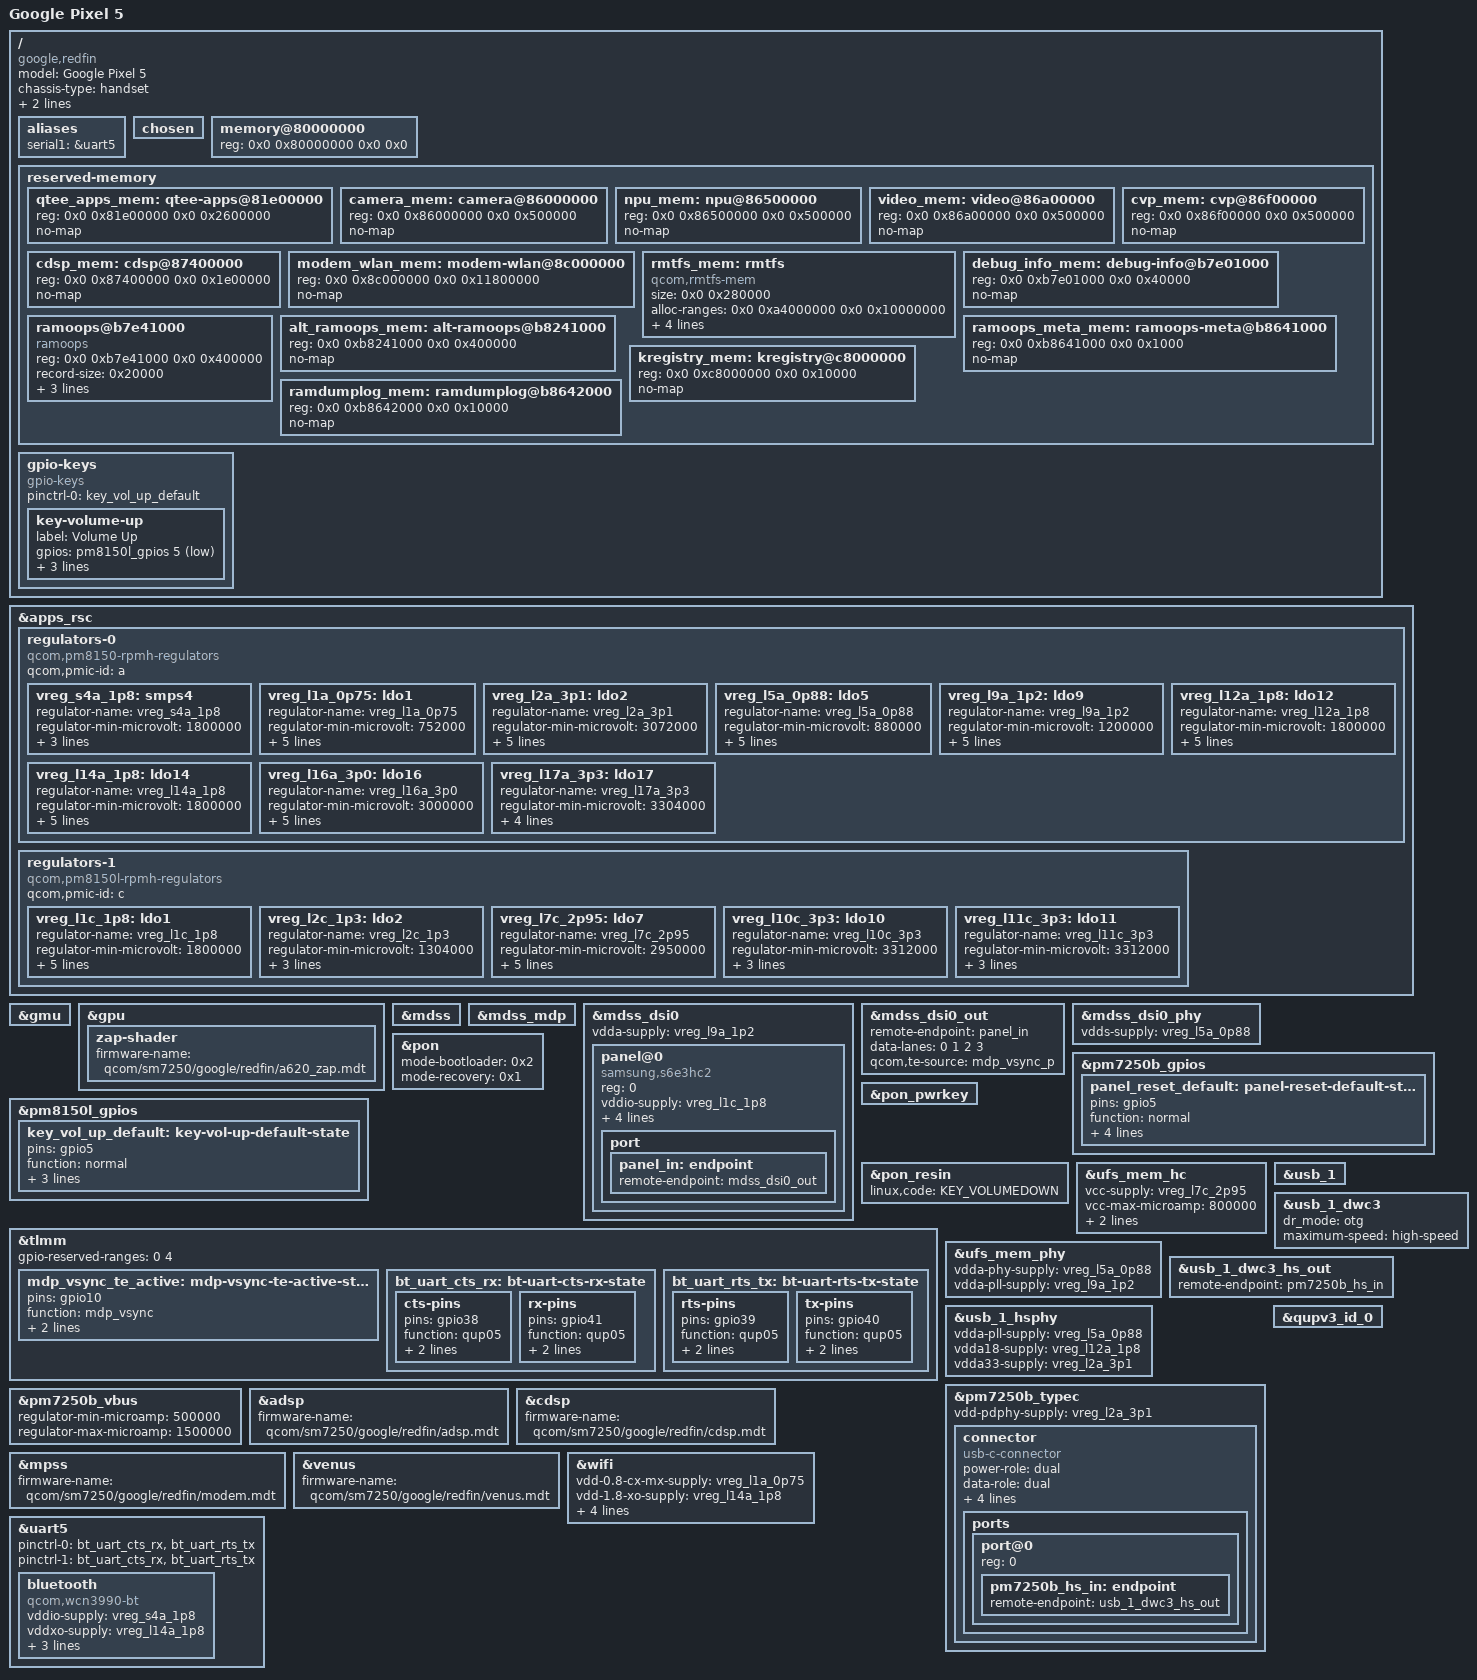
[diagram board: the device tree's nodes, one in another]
// SPDX-License-Identifier: BSD-3-Clause
/*
 * Device Tree for Google Pixel 5 (redfin) - Qualcomm Snapdragon 765G (SM7250)
 * Based on sm7250-oneplus-avicii.dts and Google Redfin stock DT (RQ3A.211001.001).
 */

/dts-v1/;

#include <dt-bindings/gpio/gpio.h>
#include <dt-bindings/input/input.h>
#include <dt-bindings/leds/common.h>
#include <dt-bindings/input/linux-event-codes.h>
#include <dt-bindings/pinctrl/qcom,pmic-gpio.h>
#include <dt-bindings/regulator/qcom,rpmh-regulator.h>

/* PM7250B is configured to use SID2/3 */
#define PM7250B_SID 2
#define PM7250B_SID1 3

#include "sm7250.dtsi"
#include "pm8150.dtsi"
#include "pm8150l.dtsi"
#include "pm7250b.dtsi"

/*
 * Remove the OnePlus OxygenOS 12 relocated PIL nodes from sm7250.dtsi
 * (0x9b800000..0x9cc00000) because Redfin uses the standard Lito layout
 * (0x86000000..0x87400000) and expands modem_wlan_mem to 0x8c000000..0x9d800000.
 */
/delete-node/ &camera_mem;
/delete-node/ &npu_mem;
/delete-node/ &video_mem;
/delete-node/ &cvp_mem;
/delete-node/ &cdsp_mem;

/ {
	model = "Google Pixel 5";
	compatible = "google,redfin", "qcom,sm7250";
	chassis-type = "handset";

	/* Matches Redfin PVT (MP1.0) in stock dtbo_1.dts */
	qcom,msm-id = <0x190 0x20000 0x1b8 0x20000>;
	qcom,board-id = <0xb1e05 0x0>;

	aliases {
		serial1 = &uart5;
	};

	chosen {
	};

	memory@80000000 {
		device_type = "memory";
		reg = <0x0 0x80000000 0x0 0x0>;
	};

	reserved-memory {
		qtee_apps_mem: qtee-apps@81e00000 {
			reg = <0x0 0x81e00000 0x0 0x2600000>;
			no-map;
		};

		camera_mem: camera@86000000 {
			reg = <0x0 0x86000000 0x0 0x500000>;
			no-map;
		};

		npu_mem: npu@86500000 {
			reg = <0x0 0x86500000 0x0 0x500000>;
			no-map;
		};

		video_mem: video@86a00000 {
			reg = <0x0 0x86a00000 0x0 0x500000>;
			no-map;
		};

		cvp_mem: cvp@86f00000 {
			reg = <0x0 0x86f00000 0x0 0x500000>;
			no-map;
		};

		cdsp_mem: cdsp@87400000 {
			reg = <0x0 0x87400000 0x0 0x1e00000>;
			no-map;
		};

		modem_wlan_mem: modem-wlan@8c000000 {
			reg = <0x0 0x8c000000 0x0 0x11800000>;
			no-map;
		};

		/*
		 * rmtfs shared memory for MPSS (client 1, size 0x280000),
		 * placed in free RAM above dfps_data_mem (0xa2400000).
		 */
		rmtfs_mem: rmtfs {
			compatible = "qcom,rmtfs-mem";
			size = <0x0 0x280000>;
			alloc-ranges = <0x0 0xa4000000 0x0 0x10000000>;
			alignment = <0x0 0x400000>;
			no-map;

			qcom,client-id = <1>;
			qcom,vmid = <15>; /* QCOM_SCM_VMID_MSS_MSA */
		};

		/* Redfin stock debug & ramoops regions (dtbo_1.dts fragment@60 & fragment@74) */
		debug_info_mem: debug-info@b7e01000 {
			reg = <0x0 0xb7e01000 0x0 0x40000>;
			no-map;
		};

		ramoops@b7e41000 {
			compatible = "ramoops";
			reg = <0x0 0xb7e41000 0x0 0x400000>;
			record-size = <0x20000>;
			console-size = <0x100000>;
			pmsg-size = <0x80000>;
			no-map;
		};

		alt_ramoops_mem: alt-ramoops@b8241000 {
			reg = <0x0 0xb8241000 0x0 0x400000>;
			no-map;
		};

		ramoops_meta_mem: ramoops-meta@b8641000 {
			reg = <0x0 0xb8641000 0x0 0x1000>;
			no-map;
		};

		ramdumplog_mem: ramdumplog@b8642000 {
			reg = <0x0 0xb8642000 0x0 0x10000>;
			no-map;
		};

		kregistry_mem: kregistry@c8000000 {
			reg = <0x0 0xc8000000 0x0 0x10000>;
			no-map;
		};
	};

	gpio-keys {
		compatible = "gpio-keys";
		pinctrl-names = "default";
		pinctrl-0 = <&key_vol_up_default>;

		key-volume-up {
			label = "Volume Up";
			gpios = <&pm8150l_gpios 5 GPIO_ACTIVE_LOW>;
			linux,code = <KEY_VOLUMEUP>;
			debounce-interval = <15>;
			wakeup-source;
		};
	};
};

&apps_rsc {
	regulators-0 {
		compatible = "qcom,pm8150-rpmh-regulators";
		qcom,pmic-id = "a";

		/* UFS vccq2 & system 1.8 V rail */
		vreg_s4a_1p8: smps4 {
			regulator-name = "vreg_s4a_1p8";
			regulator-min-microvolt = <1800000>;
			regulator-max-microvolt = <1800000>;
			regulator-boot-on;
			regulator-always-on;
		};

		/* WLAN vdd-0.8-cx-mx */
		vreg_l1a_0p75: ldo1 {
			regulator-name = "vreg_l1a_0p75";
			regulator-min-microvolt = <752000>;
			regulator-max-microvolt = <752000>;
			regulator-initial-mode = <RPMH_REGULATOR_MODE_HPM>;
			regulator-boot-on;
			regulator-always-on;
		};

		/* USB HS PHY 3.1 V & Type-C PD PHY */
		vreg_l2a_3p1: ldo2 {
			regulator-name = "vreg_l2a_3p1";
			regulator-min-microvolt = <3072000>;
			regulator-max-microvolt = <3072000>;
			regulator-initial-mode = <RPMH_REGULATOR_MODE_HPM>;
			regulator-boot-on;
			regulator-always-on;
		};

		/* USB HS PHY PLL, UFS PHY vdda, DSI0 PHY vdds (0.88 V) */
		vreg_l5a_0p88: ldo5 {
			regulator-name = "vreg_l5a_0p88";
			regulator-min-microvolt = <880000>;
			regulator-max-microvolt = <880000>;
			regulator-initial-mode = <RPMH_REGULATOR_MODE_HPM>;
			regulator-boot-on;
			regulator-always-on;
		};

		/* UFS PHY PLL & DSI0 vdda (1.2 V) */
		vreg_l9a_1p2: ldo9 {
			regulator-name = "vreg_l9a_1p2";
			regulator-min-microvolt = <1200000>;
			regulator-max-microvolt = <1200000>;
			regulator-initial-mode = <RPMH_REGULATOR_MODE_HPM>;
			regulator-boot-on;
			regulator-always-on;
		};

		/* USB HS PHY 1.8 V */
		vreg_l12a_1p8: ldo12 {
			regulator-name = "vreg_l12a_1p8";
			regulator-min-microvolt = <1800000>;
			regulator-max-microvolt = <1800000>;
			regulator-initial-mode = <RPMH_REGULATOR_MODE_HPM>;
			regulator-boot-on;
			regulator-always-on;
		};

		/* WLAN/BT vdd-1.8-xo */
		vreg_l14a_1p8: ldo14 {
			regulator-name = "vreg_l14a_1p8";
			regulator-min-microvolt = <1800000>;
			regulator-max-microvolt = <1800000>;
			regulator-initial-mode = <RPMH_REGULATOR_MODE_HPM>;
			regulator-boot-on;
			regulator-always-on;
		};

		/* Display panel vdd (3.0 V) */
		vreg_l16a_3p0: ldo16 {
			regulator-name = "vreg_l16a_3p0";
			regulator-min-microvolt = <3000000>;
			regulator-max-microvolt = <3000000>;
			regulator-initial-mode = <RPMH_REGULATOR_MODE_HPM>;
			regulator-boot-on;
			regulator-always-on;
		};

		/* Touchscreen avdd (3.304 V on Redfin fragment@86) */
		vreg_l17a_3p3: ldo17 {
			regulator-name = "vreg_l17a_3p3";
			regulator-min-microvolt = <3304000>;
			regulator-max-microvolt = <3304000>;
			regulator-initial-mode = <RPMH_REGULATOR_MODE_HPM>;
			regulator-boot-on;
		};
	};

	regulators-1 {
		compatible = "qcom,pm8150l-rpmh-regulators";
		qcom,pmic-id = "c";

		/* Display panel vddio (1.8 V) */
		vreg_l1c_1p8: ldo1 {
			regulator-name = "vreg_l1c_1p8";
			regulator-min-microvolt = <1800000>;
			regulator-max-microvolt = <1800000>;
			regulator-initial-mode = <RPMH_REGULATOR_MODE_HPM>;
			regulator-boot-on;
			regulator-always-on;
		};

		/* WLAN/BT vdd-1.3-rfa */
		vreg_l2c_1p3: ldo2 {
			regulator-name = "vreg_l2c_1p3";
			regulator-min-microvolt = <1304000>;
			regulator-max-microvolt = <1304000>;
			regulator-initial-mode = <RPMH_REGULATOR_MODE_HPM>;
		};

		/* UFS vcc (2.95 V) */
		vreg_l7c_2p95: ldo7 {
			regulator-name = "vreg_l7c_2p95";
			regulator-min-microvolt = <2950000>;
			regulator-max-microvolt = <2960000>;
			regulator-initial-mode = <RPMH_REGULATOR_MODE_HPM>;
			regulator-boot-on;
			regulator-always-on;
		};

		/* WLAN/BT vdd-3.3-ch0 */
		vreg_l10c_3p3: ldo10 {
			regulator-name = "vreg_l10c_3p3";
			regulator-min-microvolt = <3312000>;
			regulator-max-microvolt = <3312000>;
			regulator-initial-mode = <RPMH_REGULATOR_MODE_HPM>;
		};

		/* WLAN vdd-3.3-ch1 */
		vreg_l11c_3p3: ldo11 {
			regulator-name = "vreg_l11c_3p3";
			regulator-min-microvolt = <3312000>;
			regulator-max-microvolt = <3312000>;
			regulator-initial-mode = <RPMH_REGULATOR_MODE_HPM>;
		};
	};
};

&gmu {
	status = "okay";
};

&gpu {
	status = "okay";

	zap-shader {
		firmware-name = "qcom/sm7250/google/redfin/a620_zap.mdt";
	};
};

&mdss {
	status = "okay";
};

&mdss_mdp {
	status = "okay";
};

&mdss_dsi0 {
	vdda-supply = <&vreg_l9a_1p2>;

	status = "okay";

	panel@0 {
		compatible = "samsung,s6e3hc2";
		reg = <0>;

		vddio-supply = <&vreg_l1c_1p8>;
		vdd-supply = <&vreg_l16a_3p0>;

		/* Redfin panel reset is on PM7250B gpio5 (active low) */
		reset-gpios = <&pm7250b_gpios 5 GPIO_ACTIVE_LOW>;

		pinctrl-names = "default";
		pinctrl-0 = <&mdp_vsync_te_active>, <&panel_reset_default>;

		port {
			panel_in: endpoint {
				remote-endpoint = <&mdss_dsi0_out>;
			};
		};
	};
};

&mdss_dsi0_out {
	remote-endpoint = <&panel_in>;
	data-lanes = <0 1 2 3>;
	qcom,te-source = "mdp_vsync_p";
};

&mdss_dsi0_phy {
	vdds-supply = <&vreg_l5a_0p88>;

	status = "okay";
};

&pm7250b_gpios {
	/* Downstream disp_pins_default on PM7250B gpio5 */
	panel_reset_default: panel-reset-default-state {
		pins = "gpio5";
		function = "normal";
		power-source = <1>;
		bias-disable;
		output-high;
		qcom,drive-strength = <PMIC_GPIO_STRENGTH_MED>;
	};
};

&pm8150l_gpios {
	key_vol_up_default: key-vol-up-default-state {
		pins = "gpio5";
		function = "normal";
		input-enable;
		bias-pull-up;
		power-source = <0>;
	};
};

&pon {
	mode-bootloader = <0x2>;
	mode-recovery = <0x1>;
};

&pon_pwrkey {
	status = "okay";
};

&pon_resin {
	linux,code = <KEY_VOLUMEDOWN>;
	status = "okay";
};

&tlmm {
	/* TZ-owned GPIOs on Redfin (dtbo_1.dts fragment@63: goog,ignored-gpios = <0 1 2 3>) */
	gpio-reserved-ranges = <0 4>;

	mdp_vsync_te_active: mdp-vsync-te-active-state {
		pins = "gpio10";
		function = "mdp_vsync";
		drive-strength = <2>;
		bias-pull-down;
	};

	bt_uart_cts_rx: bt-uart-cts-rx-state {
		cts-pins {
			pins = "gpio38";
			function = "qup05";
			drive-strength = <2>;
			bias-pull-down;
		};

		rx-pins {
			pins = "gpio41";
			function = "qup05";
			drive-strength = <2>;
			bias-pull-up;
		};
	};

	bt_uart_rts_tx: bt-uart-rts-tx-state {
		rts-pins {
			pins = "gpio39";
			function = "qup05";
			drive-strength = <2>;
			bias-pull-down;
		};

		tx-pins {
			pins = "gpio40";
			function = "qup05";
			drive-strength = <2>;
			bias-pull-up;
		};
	};
};

&ufs_mem_hc {
	vcc-supply = <&vreg_l7c_2p95>;
	vcc-max-microamp = <800000>;
	vccq2-supply = <&vreg_s4a_1p8>;
	vccq2-max-microamp = <800000>;

	status = "okay";
};

&ufs_mem_phy {
	vdda-phy-supply = <&vreg_l5a_0p88>;
	vdda-pll-supply = <&vreg_l9a_1p2>;

	status = "okay";
};

&usb_1 {
	status = "okay";
};

&usb_1_dwc3 {
	dr_mode = "otg";
	maximum-speed = "high-speed";
};

&usb_1_dwc3_hs_out {
	remote-endpoint = <&pm7250b_hs_in>;
};

&usb_1_hsphy {
	vdda-pll-supply = <&vreg_l5a_0p88>;
	vdda18-supply = <&vreg_l12a_1p8>;
	vdda33-supply = <&vreg_l2a_3p1>;

	status = "okay";
};

&pm7250b_typec {
	vdd-pdphy-supply = <&vreg_l2a_3p1>;

	status = "okay";

	connector {
		compatible = "usb-c-connector";

		power-role = "dual";
		data-role = "dual";
		self-powered;

		typec-power-opmode = "default";
		pd-disable;

		vbus-supply = <&pm7250b_vbus>;

		ports {
			#address-cells = <1>;
			#size-cells = <0>;

			port@0 {
				reg = <0>;

				pm7250b_hs_in: endpoint {
					remote-endpoint = <&usb_1_dwc3_hs_out>;
				};
			};
		};
	};
};

&pm7250b_vbus {
	regulator-min-microamp = <500000>;
	regulator-max-microamp = <1500000>;

	status = "okay";
};

&adsp {
	firmware-name = "qcom/sm7250/google/redfin/adsp.mdt";

	status = "okay";
};

&cdsp {
	firmware-name = "qcom/sm7250/google/redfin/cdsp.mdt";

	status = "okay";
};

&mpss {
	firmware-name = "qcom/sm7250/google/redfin/modem.mdt";

	status = "okay";
};

&venus {
	firmware-name = "qcom/sm7250/google/redfin/venus.mdt";

	status = "okay";
};

&wifi {
	vdd-0.8-cx-mx-supply = <&vreg_l1a_0p75>;
	vdd-1.8-xo-supply = <&vreg_l14a_1p8>;
	vdd-1.3-rfa-supply = <&vreg_l2c_1p3>;
	vdd-3.3-ch0-supply = <&vreg_l10c_3p3>;
	vdd-3.3-ch1-supply = <&vreg_l11c_3p3>;

	/* Loads ath10k/WCN3990/hw1.0/redfin/board-2.bin */
	firmware-name = "redfin";

	status = "okay";
};

&qupv3_id_0 {
	status = "okay";
};

&uart5 {
	pinctrl-0 = <&bt_uart_cts_rx>, <&bt_uart_rts_tx>;
	pinctrl-1 = <&bt_uart_cts_rx>, <&bt_uart_rts_tx>;
	status = "okay";

	bluetooth {
		compatible = "qcom,wcn3990-bt";

		vddio-supply = <&vreg_s4a_1p8>;
		vddxo-supply = <&vreg_l14a_1p8>;
		vddrf-supply = <&vreg_l2c_1p3>;
		vddch0-supply = <&vreg_l10c_3p3>;

		max-speed = <3200000>;
	};
};
